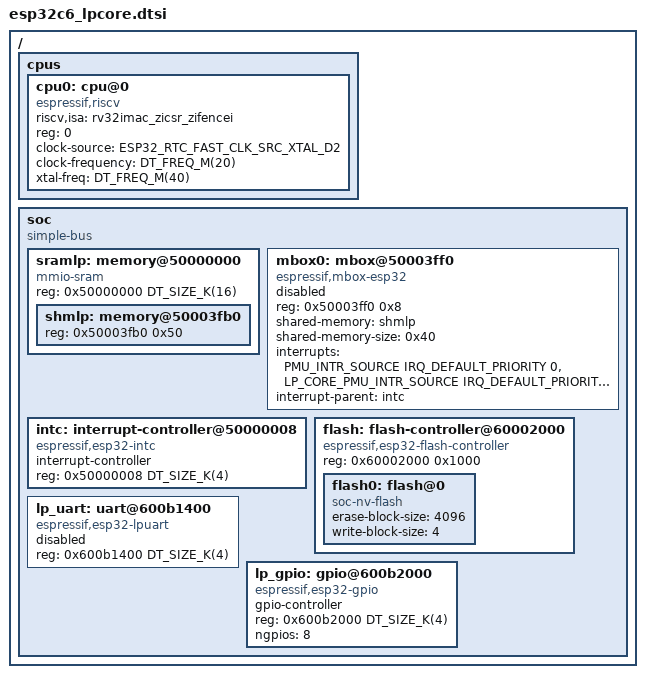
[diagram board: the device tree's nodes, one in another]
/*
 * Copyright (c) 2025 Espressif Systems (Shanghai) Co., Ltd.
 *
 * SPDX-License-Identifier: Apache-2.0
 */
#include <mem.h>
#include <freq.h>
#include <zephyr/dt-bindings/gpio/gpio.h>
#include <zephyr/dt-bindings/interrupt-controller/esp-esp32c6-intmux.h>
#include <zephyr/dt-bindings/clock/esp32c6_clock.h>
#include <dt-bindings/pinctrl/esp32c6-pinctrl.h>

/ {
	#address-cells = <1>;
	#size-cells = <1>;

	cpus {
		#address-cells = <1>;
		#size-cells = <0>;

		cpu0: cpu@0 {
			device_type = "cpu";
			compatible = "espressif,riscv";
			riscv,isa = "rv32imac_zicsr_zifencei";
			reg = <0>;
			clock-source = <ESP32_RTC_FAST_CLK_SRC_XTAL_D2>;
			clock-frequency = <DT_FREQ_M(20)>;
			xtal-freq = <DT_FREQ_M(40)>;
		};
	};

	soc {
		#address-cells = <1>;
		#size-cells = <1>;
		compatible = "simple-bus";
		ranges;

		sramlp: memory@50000000 {
			#address-cells = <1>;
			#size-cells = <1>;
			compatible = "mmio-sram";
			reg = <0x50000000 DT_SIZE_K(16)>;

			shmlp: memory@50003fb0{
				reg = <0x50003fb0 0x50>;
			};
		};

		mbox0: mbox@50003ff0 {
			compatible = "espressif,mbox-esp32";
			reg = <0x50003ff0 0x8>;
			status = "disabled";
			shared-memory = <&shmlp>;
			shared-memory-size = <0x40>;
			interrupts =
				<PMU_INTR_SOURCE IRQ_DEFAULT_PRIORITY 0>,
				<LP_CORE_PMU_INTR_SOURCE IRQ_DEFAULT_PRIORITY 0>;
			interrupt-parent = <&intc>;
			#mbox-cells = <1>;
		};

		intc: interrupt-controller@50000008 {
			compatible = "espressif,esp32-intc";
			#address-cells = <0>;
			#interrupt-cells = <3>;
			interrupt-controller;
			reg = <0x50000008 DT_SIZE_K(4)>;
			status = "okay";
		};

		flash: flash-controller@60002000 {
			compatible = "espressif,esp32-flash-controller";
			reg = <0x60002000 0x1000>;
			#address-cells = <1>;
			#size-cells = <1>;

			flash0: flash@0 {
				compatible = "soc-nv-flash";
				erase-block-size = <4096>;
				write-block-size = <4>;
				/* Flash size is specified in SOC/SIP dtsi */
			};
		};

		lp_uart: uart@600b1400 {
			compatible = "espressif,esp32-lpuart";
			reg = <0x600b1400 DT_SIZE_K(4)>;
			status = "disabled";
		};

		lp_gpio: gpio@600b2000 {
			compatible = "espressif,esp32-gpio";
			gpio-controller;
			#gpio-cells = <2>;
			reg = <0x600b2000 DT_SIZE_K(4)>;
			ngpios = <8>;
		};
	};
};
